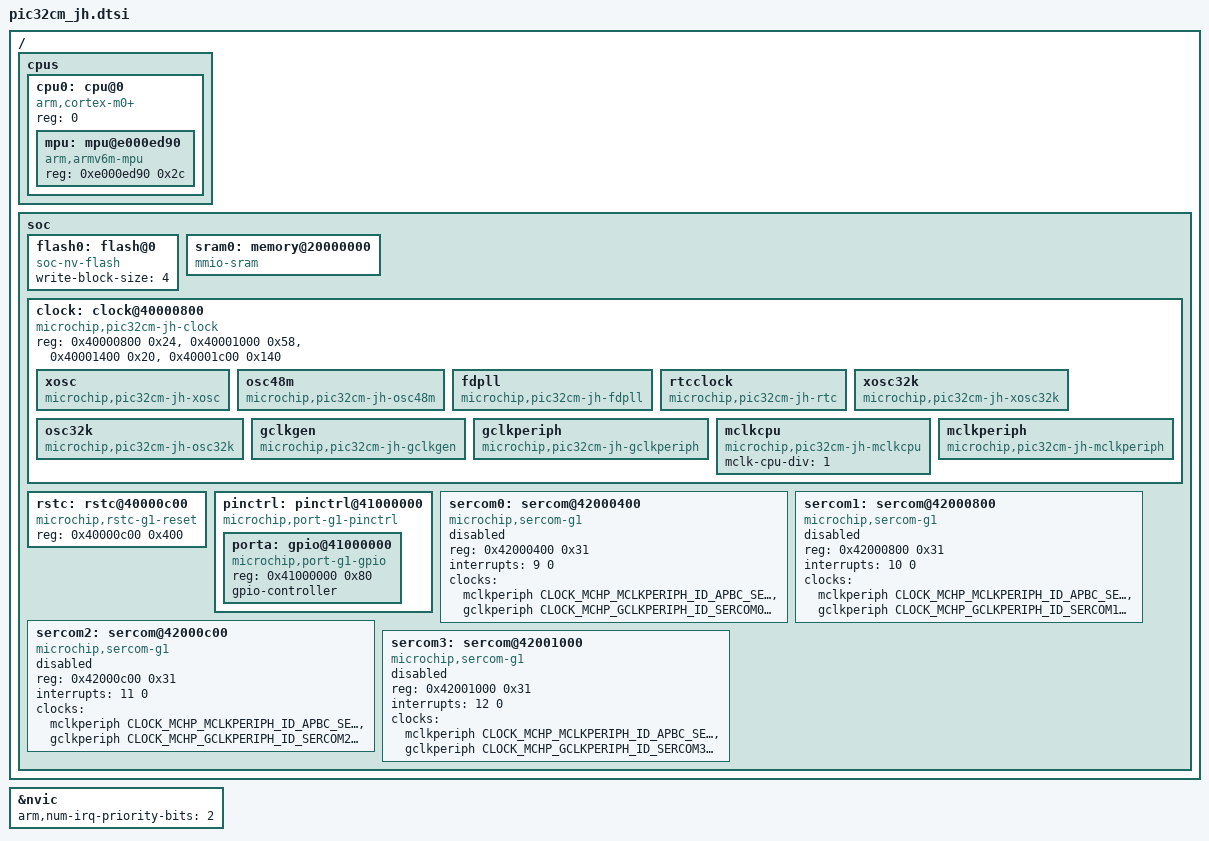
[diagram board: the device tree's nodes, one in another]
/*
 * Copyright (c) 2025-2026 Microchip Technology Inc.
 *
 * SPDX-License-Identifier: Apache-2.0
 */

/* Common SoC definitions shared across all PIC32CM JH devices */

#include <arm/armv6-m.dtsi>
#include <zephyr/dt-bindings/gpio/gpio.h>
#include <zephyr/dt-bindings/clock/mchp_pic32cm_jh_clock.h>

/ {
	cpus {
		#address-cells = <1>;
		#size-cells = <0>;

		cpu0: cpu@0 {
			device_type = "cpu";
			compatible = "arm,cortex-m0+";
			reg = <0>;
			#address-cells = <1>;
			#size-cells = <1>;

			mpu: mpu@e000ed90 {
				compatible = "arm,armv6m-mpu";
				reg = <0xe000ed90 0x2c>;
			};
		};
	};

	soc {
		flash0: flash@0 {
			compatible = "soc-nv-flash";
			write-block-size = <4>;
		};

		sram0: memory@20000000 {
			compatible = "mmio-sram";
		};

		clock: clock@40000800 {
			compatible = "microchip,pic32cm-jh-clock";
			reg = <0x40000800 0x24>, <0x40001000 0x58>,
			      <0x40001400 0x20>, <0x40001c00 0x140>;
			reg-names = "mclk", "oscctrl",
				    "osc32kctrl", "gclk";

			xosc: xosc {
				compatible = "microchip,pic32cm-jh-xosc";
			};

			osc48m: osc48m {
				compatible = "microchip,pic32cm-jh-osc48m";
			};

			fdpll: fdpll {
				compatible = "microchip,pic32cm-jh-fdpll";
			};

			rtcclock: rtcclock {
				compatible = "microchip,pic32cm-jh-rtc";
				#clock-cells = <1>;
			};

			xosc32k: xosc32k {
				compatible = "microchip,pic32cm-jh-xosc32k";
			};

			osc32k: osc32k {
				compatible = "microchip,pic32cm-jh-osc32k";
			};

			gclkgen: gclkgen {
				compatible = "microchip,pic32cm-jh-gclkgen";
			};

			gclkperiph: gclkperiph {
				compatible = "microchip,pic32cm-jh-gclkperiph";
				#clock-cells = <1>;
			};

			mclkcpu: mclkcpu {
				compatible = "microchip,pic32cm-jh-mclkcpu";
				mclk-cpu-div = <1>;
			};

			mclkperiph: mclkperiph {
				compatible = "microchip,pic32cm-jh-mclkperiph";
				#clock-cells = <1>;
			};
		};

		rstc: rstc@40000c00 {
			compatible = "microchip,rstc-g1-reset";
			reg = <0x40000c00 0x400>;
		};

		pinctrl: pinctrl@41000000 {
			compatible = "microchip,port-g1-pinctrl";
			#address-cells = <1>;
			#size-cells = <1>;
			ranges = <0x41000000 0x41000000 0x180>;

			porta: gpio@41000000 {
				compatible = "microchip,port-g1-gpio";
				reg = <0x41000000 0x80>;
				gpio-controller;
				#gpio-cells = <2>;
				#microchip,pin-cells = <2>;
			};
		};

		sercom0: sercom@42000400 {
			compatible = "microchip,sercom-g1";
			reg = <0x42000400 0x31>;
			interrupts = <9 0>;
			interrupt-names = "source-0-7";
			clocks = <&mclkperiph CLOCK_MCHP_MCLKPERIPH_ID_APBC_SERCOM0>,
				 <&gclkperiph CLOCK_MCHP_GCLKPERIPH_ID_SERCOM0_CORE>;
			clock-names = "mclk", "gclk";
			status = "disabled";
		};

		sercom1: sercom@42000800 {
			compatible = "microchip,sercom-g1";
			reg = <0x42000800 0x31>;
			interrupts = <10 0>;
			interrupt-names = "source-0-7";
			clocks = <&mclkperiph CLOCK_MCHP_MCLKPERIPH_ID_APBC_SERCOM1>,
				 <&gclkperiph CLOCK_MCHP_GCLKPERIPH_ID_SERCOM1_CORE>;
			clock-names = "mclk", "gclk";
			status = "disabled";
		};

		sercom2: sercom@42000c00 {
			compatible = "microchip,sercom-g1";
			reg = <0x42000c00 0x31>;
			interrupts = <11 0>;
			interrupt-names = "source-0-7";
			clocks = <&mclkperiph CLOCK_MCHP_MCLKPERIPH_ID_APBC_SERCOM2>,
				 <&gclkperiph CLOCK_MCHP_GCLKPERIPH_ID_SERCOM2_CORE>;
			clock-names = "mclk", "gclk";
			status = "disabled";
		};

		sercom3: sercom@42001000 {
			compatible = "microchip,sercom-g1";
			reg = <0x42001000 0x31>;
			interrupts = <12 0>;
			interrupt-names = "source-0-7";
			clocks = <&mclkperiph CLOCK_MCHP_MCLKPERIPH_ID_APBC_SERCOM3>,
				 <&gclkperiph CLOCK_MCHP_GCLKPERIPH_ID_SERCOM3_CORE>;
			clock-names = "mclk", "gclk";
			status = "disabled";
		};
	};
};

&nvic {
	arm,num-irq-priority-bits = <2>;
};
